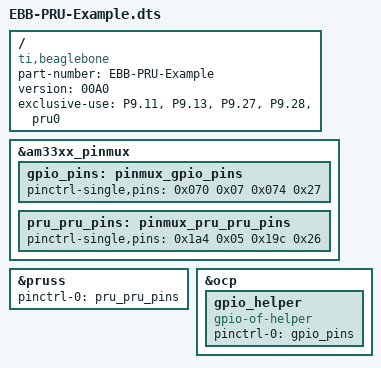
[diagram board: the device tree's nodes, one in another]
/dts-v1/;
/plugin/;

/ {
	compatible = "ti,beaglebone", "ti,beaglebone-black";

	part-number = "EBB-PRU-Example";	/* identification */
	version = "00A0";					/* version */

	/* This overlay uses the following resources */
	exclusive-use = "P9.11", "P9.13", "P9.27", "P9.28", "pru0";

	fragment@0 {
		target = <&am33xx_pinmux>;
		__overlay__ {
			gpio_pins: pinmux_gpio_pins {
				pinctrl-single,pins = <
					0x070 0x07
					0x074 0x27
				>;
			};
			pru_pru_pins: pinmux_pru_pru_pins {
				pinctrl-single,pins = <
					0x1a4 0x05
					0x19c 0x26
				>;
			};
		};
	};
	
	fragment@1 {
		target = <&pruss>;
		__overlay__ {
			status = "okay";
			pinctrl-names = "default";
			pinctrl-0 = <&pru_pru_pins>;
		};
	};

	fragment@2 {
		target = <&ocp>;
		__overlay__ {
			gpio_helper {
				compatible = "gpio-of-helper";
				status = "okay";
				pinctrl-names = "default";
				pinctrl-0 = <&gpio_pins>;
			};
		};
	};
};
